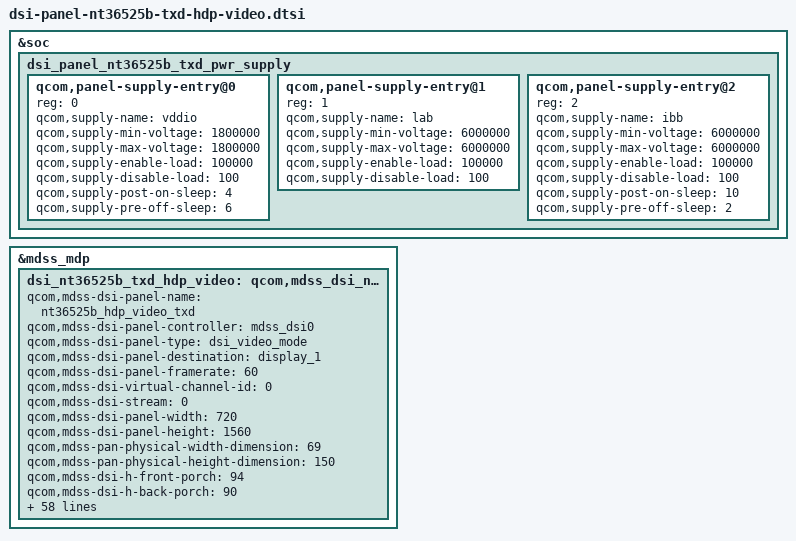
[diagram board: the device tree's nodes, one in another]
/* Copyright (c) 2013, The Linux Foundation. All rights reserved.
 *
 * This program is free software; you can redistribute it and/or modify
 * it under the terms of the GNU General Public License version 2 and
 * only version 2 as published by the Free Software Foundation.
 *
 * This program is distributed in the hope that it will be useful,
 * but WITHOUT ANY WARRANTY; without even the implied warranty of
 * MERCHANTABILITY or FITNESS FOR A PARTICULAR PURPOSE.  See the
 * GNU General Public License for more details.
 */

/*---------------------------------------------------------------------------
 * This file is autogenerated file using gcdb parser. Please do not edit it.
 * Update input XML file to add a new entry or update variable in this file
 * VERSION = "1.0"
 *---------------------------------------------------------------------------*/
&soc {
	dsi_panel_nt36525b_txd_pwr_supply: dsi_panel_nt36525b_txd_pwr_supply {
		#address-cells = <1>;
		#size-cells = <0>;

		qcom,panel-supply-entry@0 {
			reg = <0>;
			qcom,supply-name = "vddio";
			qcom,supply-min-voltage = <1800000>;
			qcom,supply-max-voltage = <1800000>;
			qcom,supply-enable-load = <100000>;
			qcom,supply-disable-load = <100>;
			qcom,supply-post-on-sleep = <4>;
			qcom,supply-pre-off-sleep = <6>;
		};
		qcom,panel-supply-entry@1 {
			reg = <1>;
			qcom,supply-name = "lab";
			qcom,supply-min-voltage = <6000000>;
			qcom,supply-max-voltage = <6000000>;
			qcom,supply-enable-load = <100000>;
			qcom,supply-disable-load = <100>;
		};
		qcom,panel-supply-entry@2 {
			reg = <2>;
			qcom,supply-name = "ibb";
			qcom,supply-min-voltage = <6000000>;
			qcom,supply-max-voltage = <6000000>;
			qcom,supply-enable-load = <100000>;
			qcom,supply-disable-load = <100>;
			qcom,supply-post-on-sleep = <10>;
			qcom,supply-pre-off-sleep = <2>;
		};
	};
};
&mdss_mdp {
	dsi_nt36525b_txd_hdp_video: qcom,mdss_dsi_nt36525b_txd_hdp_video {
		qcom,mdss-dsi-panel-name = "nt36525b_hdp_video_txd";
		qcom,mdss-dsi-panel-controller = <&mdss_dsi0>;
		qcom,mdss-dsi-panel-type = "dsi_video_mode";
		qcom,mdss-dsi-panel-destination = "display_1";
		qcom,mdss-dsi-panel-framerate = <60>;
		qcom,mdss-dsi-virtual-channel-id = <0>;
		qcom,mdss-dsi-stream = <0>;
		qcom,mdss-dsi-panel-width = <720>;
		qcom,mdss-dsi-panel-height = <1560>;
		qcom,mdss-pan-physical-width-dimension = <69>;
		qcom,mdss-pan-physical-height-dimension = <150>;
		qcom,mdss-dsi-h-front-porch = <94>;
		qcom,mdss-dsi-h-back-porch = <90>;
		qcom,mdss-dsi-h-pulse-width = <4>;
		qcom,mdss-dsi-h-sync-skew = <0>;
		qcom,mdss-dsi-v-back-porch = <242>;
		qcom,mdss-dsi-v-front-porch = <10>;
		qcom,mdss-dsi-v-pulse-width = <2>;
		qcom,mdss-dsi-h-left-border = <0>;
		qcom,mdss-dsi-h-right-border = <0>;
		qcom,mdss-dsi-v-top-border = <0>;
		qcom,mdss-dsi-v-bottom-border = <0>;
		qcom,mdss-dsi-bpp = <24>;
		qcom,mdss-dsi-color-order = "rgb_swap_rgb";
		qcom,mdss-dsi-underflow-color = <0xff>;
		qcom,mdss-dsi-border-color = <0>;
		qcom,mdss-dsi-on-command = [39 01 00 00 00 00 02 FF 20
					39 01 00 00 00 00 02 FB 01
					39 01 00 00 00 00 02 03 54
					39 01 00 00 00 00 02 05 B1
					39 01 00 00 00 00 02 07 6E
					39 01 00 00 00 00 02 08 CB
					39 01 00 00 00 00 02 0E 87
					39 01 00 00 00 00 02 0F 69
					39 01 00 00 00 00 02 69 A9
					39 01 00 00 00 00 02 88 00
					39 01 00 00 00 00 02 95 D7
					39 01 00 00 00 00 02 96 D7
					39 01 00 00 00 00 02 FF 23
					39 01 00 00 00 00 02 FB 01
					39 01 00 00 00 00 02 00 68
					39 01 00 00 00 00 02 07 00
					39 01 00 00 00 00 02 08 01
					39 01 00 00 00 00 02 09 00
					39 01 00 00 00 00 02 12 B0
					39 01 00 00 00 00 02 15 EF
					39 01 00 00 00 00 02 16 0B
					39 01 00 00 00 00 02 FF 24
					39 01 00 00 00 00 02 FB 01
					39 01 00 00 00 00 02 00 05
					39 01 00 00 00 00 02 01 00
					39 01 00 00 00 00 02 02 1F
					39 01 00 00 00 00 02 03 1E
					39 01 00 00 00 00 02 04 20
					39 01 00 00 00 00 02 05 00
					39 01 00 00 00 00 02 06 00
					39 01 00 00 00 00 02 07 00
					39 01 00 00 00 00 02 08 00
					39 01 00 00 00 00 02 09 0F
					39 01 00 00 00 00 02 0A 0E
					39 01 00 00 00 00 02 0B 00
					39 01 00 00 00 00 02 0C 00
					39 01 00 00 00 00 02 0D 0D
					39 01 00 00 00 00 02 0E 0C
					39 01 00 00 00 00 02 0F 04
					39 01 00 00 00 00 02 10 00
					39 01 00 00 00 00 02 11 00
					39 01 00 00 00 00 02 12 00
					39 01 00 00 00 00 02 13 00
					39 01 00 00 00 00 02 14 00
					39 01 00 00 00 00 02 15 00
					39 01 00 00 00 00 02 16 05
					39 01 00 00 00 00 02 17 00
					39 01 00 00 00 00 02 18 1F
					39 01 00 00 00 00 02 19 1E
					39 01 00 00 00 00 02 1A 20
					39 01 00 00 00 00 02 1B 00
					39 01 00 00 00 00 02 1C 00
					39 01 00 00 00 00 02 1D 00
					39 01 00 00 00 00 02 1E 00
					39 01 00 00 00 00 02 1F 0F
					39 01 00 00 00 00 02 20 0E
					39 01 00 00 00 00 02 21 00
					39 01 00 00 00 00 02 22 00
					39 01 00 00 00 00 02 23 0D
					39 01 00 00 00 00 02 24 0C
					39 01 00 00 00 00 02 25 04
					39 01 00 00 00 00 02 26 00
					39 01 00 00 00 00 02 27 00
					39 01 00 00 00 00 02 28 00
					39 01 00 00 00 00 02 29 00
					39 01 00 00 00 00 02 2A 00
					39 01 00 00 00 00 02 2B 00
					39 01 00 00 00 00 02 2F 06
					39 01 00 00 00 00 02 30 30
					39 01 00 00 00 00 02 33 30
					39 01 00 00 00 00 02 34 06
					39 01 00 00 00 00 02 37 74
					39 01 00 00 00 00 02 3A 9D
					39 01 00 00 00 00 02 3B AB
					39 01 00 00 00 00 02 3D 52
					39 01 00 00 00 00 02 4D 12
					39 01 00 00 00 00 02 4E 34
					39 01 00 00 00 00 02 51 43
					39 01 00 00 00 00 02 52 21
					39 01 00 00 00 00 02 55 42
					39 01 00 00 00 00 02 56 34
					39 01 00 00 00 00 02 5A 9D
					39 01 00 00 00 00 02 5B AB
					39 01 00 00 00 00 02 5C 00
					39 01 00 00 00 00 02 5D 00
					39 01 00 00 00 00 02 5E 08
					39 01 00 00 00 00 02 60 80
					39 01 00 00 00 00 02 61 86
					39 01 00 00 00 00 02 64 11
					39 01 00 00 00 00 02 92 B8
					39 01 00 00 00 00 02 93 0A
					39 01 00 00 00 00 02 94 0A
					39 01 00 00 00 00 02 AB 00
					39 01 00 00 00 00 02 AD 00
					39 01 00 00 00 00 02 B0 05
					39 01 00 00 00 00 02 B1 B4
					39 01 00 00 00 00 02 FF 25
					39 01 00 00 00 00 02 FB 01
					39 01 00 00 00 00 02 0A 82
					39 01 00 00 00 00 02 0B 35
					39 01 00 00 00 00 02 0C 01
					39 01 00 00 00 00 02 17 82
					39 01 00 00 00 00 02 18 06
					39 01 00 00 00 00 02 19 0F
					39 01 00 00 00 00 02 FF 26
					39 01 00 00 00 00 02 FB 01
					39 01 00 00 00 00 02 00 A0
					39 01 00 00 00 00 02 FF 27
					39 01 00 00 00 00 02 FB 01
					39 01 00 00 00 00 02 13 00
					39 01 00 00 00 00 02 15 B4
					39 01 00 00 00 00 02 1F 55
					39 01 00 00 00 00 02 26 0F
					39 01 00 00 00 00 02 C0 18
					39 01 00 00 00 00 02 C1 EA
					39 01 00 00 00 00 02 C2 00
					39 01 00 00 00 00 02 C3 00
					39 01 00 00 00 00 02 C4 EA
					39 01 00 00 00 00 02 C5 00
					39 01 00 00 00 00 02 C6 00
					39 01 00 00 00 00 02 FF 23
					39 01 00 00 00 00 02 FB 01
					39 01 00 00 00 00 02 29 3F
					39 01 00 00 00 00 02 30 FF
					39 01 00 00 00 00 02 31 F8
					39 01 00 00 00 00 02 32 EF
					39 01 00 00 00 00 02 33 E8
					39 01 00 00 00 00 02 34 E2
					39 01 00 00 00 00 02 35 DA
					39 01 00 00 00 00 02 36 D4
					39 01 00 00 00 00 02 37 CD
					39 01 00 00 00 00 02 38 C8
					39 01 00 00 00 00 02 39 C2
					39 01 00 00 00 00 02 3A BD
					39 01 00 00 00 00 02 3B B8
					39 01 00 00 00 00 02 3D B3
					39 01 00 00 00 00 02 3F AE
					39 01 00 00 00 00 02 40 AA
					39 01 00 00 00 00 02 41 A6
					39 01 00 00 00 00 02 FF 10
					39 01 00 00 00 00 02 FB 01
					39 01 00 00 00 00 02 BA 03
					39 01 00 00 00 00 02 35 00
					39 01 00 00 00 00 03 51 00 00
					39 01 00 00 00 00 03 68 02 01
					39 01 00 00 00 00 02 53 24
					39 01 00 00 00 00 02 55 00
					05 01 00 00 14 00 02 29 00
					05 01 00 00 78 00 02 11 00
					];
		qcom,mdss-dsi-off-command = [05 01 00 00 14 00 02 28 00
					05 01 00 00 78 00 02 10 00];
		qcom,mdss-dsi-on-command-state = "dsi_lp_mode";
		qcom,mdss-dsi-off-command-state = "dsi_lp_mode";
		qcom,mdss-dsi-h-sync-pulse = <1>;
		qcom,mdss-dsi-traffic-mode = "burst_mode";
		qcom,mdss-dsi-lane-map = "lane_map_0123";
		qcom,mdss-dsi-bllp-eof-power-mode;
		qcom,mdss-dsi-bllp-power-mode;
		qcom,mdss-dsi-lane-0-state;
		qcom,mdss-dsi-lane-1-state;
		qcom,mdss-dsi-lane-2-state;
		qcom,mdss-dsi-lane-3-state;
		//qcom,suspend-ulps-enabled;

		qcom,mdss-dsi-panel-timings-phy-v2 = [20 1C 06 07 03 03 04 a0
						20 1C 06 07 03 03 04 a0
						20 1C 06 07 03 03 04 a0
						20 1C 06 07 03 03 04 a0
						20 12 05 06 03 03 04 a0];
		qcom,mdss-dsi-t-clk-post = <0x0B>;
		qcom,mdss-dsi-t-clk-pre = <0x24>;
		qcom,mdss-dsi-bl-pmic-control-type = "bl_ctrl_dcs";
		qcom,mdss-dsi-bl-min-level = <1>;
		qcom,mdss-dsi-bl-max-level = <255>;
		ss,blmap-size = <256>;
		ss,blmap = < 0 1 1 1 1 1 1 1 1 1
					1 1 2 3 4 5 6 7 8 9
					10 11 12 13 14 15 16 17 18 19
					20 21 22 23 24 25 26 27 28 29
					30 31 32 33 34 35 36 37 38 39
					40 41 42 43 44 45 46 47 48 49
					50 51 52 53 54 55 56 57 58 59
					60 61 62 63 64 65 66 67 68 69
					70 71 72 73 74 75 76 77 78 79
					80 81 82 83 84 85 86 87 88 89
					90 91 92 93 94 95 96 97 98 99
					100 101 102 103 104 105 106 107 108 109
					110 111 112 113 114 115 116 117 118 119
					120 121 122 123 124 125 126 127 128 129
					130 131 132 133 134 135 136 137 138 139
					140 141 142 143 144 145 146 147 148 149
					150 151 152 153 154 155 156 157 158 159
					160 161 162 163 164 165 166 167 168 169
					170 171 172 173 174 175 176 177 178 179
					180 181 182 183 184 185 186 187 188 189
					190 191 192 193 194 195 196 197 198 199
					200 201 202 203 204 205 206 207 208 209
					210 211 212 213 214 215 216 217 218 219
					220 221 222 223 224 225 226 227 228 229
					230 231 232 233 234 236 238 240 242 244
					246 248 250 252 254 255>;
		qcom,mdss-dsi-dma-trigger = "trigger_sw";
		qcom,mdss-dsi-mdp-trigger = "none";
		qcom,mdss-dsi-lp11-init;
		qcom,mdss-dsi-init-delay-us = <5000>;
		qcom,mdss-dsi-reset-sequence = <1 10>, <0 5>, <1 10>;
		qcom,panel-name-id = <3>;
		qcom,esd-check-enabled;
		qcom,mdss-dsi-panel-status-command = [06 01 00 01 05 00 02 0A 08];
		qcom,mdss-dsi-panel-status-command-state = "dsi_lp_mode";
		qcom,mdss-dsi-panel-status-check-mode = "reg_read";
		qcom,mdss-dsi-panel-status-valid-params = <1>;
		qcom,mdss-dsi-panel-status-value = <0x9C>;
		qcom,mdss-dsi-panel-status-read-length = <1>;
		qcom,mdss-dsi-tx-eot-append;
		qcom,panel-supply-entries = <&dsi_panel_ft8006p_tianma_pwr_supply>;
	};
};
